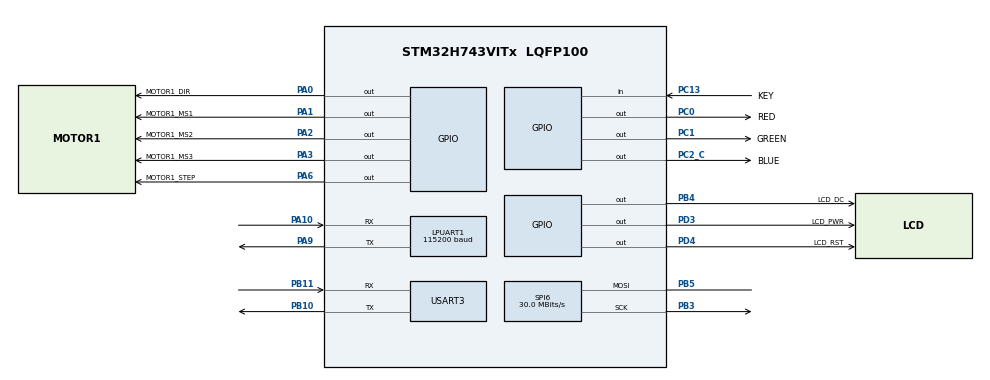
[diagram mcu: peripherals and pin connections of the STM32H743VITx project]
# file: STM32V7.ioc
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Bdma.LPUART1_RX.0.Direction=DMA_PERIPH_TO_MEMORY
Bdma.LPUART1_RX.0.EventEnable=DISABLE
Bdma.LPUART1_RX.0.Instance=BDMA_Channel0
Bdma.LPUART1_RX.0.MemDataAlignment=DMA_MDATAALIGN_BYTE
Bdma.LPUART1_RX.0.MemInc=DMA_MINC_ENABLE
Bdma.LPUART1_RX.0.Mode=DMA_NORMAL
Bdma.LPUART1_RX.0.PeriphDataAlignment=DMA_PDATAALIGN_BYTE
Bdma.LPUART1_RX.0.PeriphInc=DMA_PINC_DISABLE
Bdma.LPUART1_RX.0.Polarity=HAL_DMAMUX_REQ_GEN_RISING
Bdma.LPUART1_RX.0.Priority=DMA_PRIORITY_MEDIUM
Bdma.LPUART1_RX.0.RequestNumber=1
Bdma.LPUART1_RX.0.SignalID=NONE
Bdma.LPUART1_RX.0.SyncEnable=DISABLE
Bdma.LPUART1_RX.0.SyncPolarity=HAL_DMAMUX_SYNC_NO_EVENT
Bdma.LPUART1_RX.0.SyncRequestNumber=1
Bdma.LPUART1_RX.0.SyncSignalID=NONE
Bdma.LPUART1_TX.1.Direction=DMA_MEMORY_TO_PERIPH
Bdma.LPUART1_TX.1.EventEnable=DISABLE
Bdma.LPUART1_TX.1.Instance=BDMA_Channel1
Bdma.LPUART1_TX.1.MemDataAlignment=DMA_MDATAALIGN_BYTE
Bdma.LPUART1_TX.1.MemInc=DMA_MINC_ENABLE
Bdma.LPUART1_TX.1.Mode=DMA_NORMAL
Bdma.LPUART1_TX.1.PeriphDataAlignment=DMA_PDATAALIGN_BYTE
Bdma.LPUART1_TX.1.PeriphInc=DMA_PINC_DISABLE
Bdma.LPUART1_TX.1.Polarity=HAL_DMAMUX_REQ_GEN_RISING
Bdma.LPUART1_TX.1.Priority=DMA_PRIORITY_MEDIUM
Bdma.LPUART1_TX.1.RequestNumber=1
Bdma.LPUART1_TX.1.SignalID=NONE
Bdma.LPUART1_TX.1.SyncEnable=DISABLE
Bdma.LPUART1_TX.1.SyncPolarity=HAL_DMAMUX_SYNC_NO_EVENT
Bdma.LPUART1_TX.1.SyncRequestNumber=1
Bdma.LPUART1_TX.1.SyncSignalID=NONE
Bdma.Request0=LPUART1_RX
Bdma.Request1=LPUART1_TX
Bdma.RequestsNb=2
CORTEX_M7.AccessPermission-Cortex_Memory_Protection_Unit_Region1_Settings=MPU_REGION_PRIV_RO
CORTEX_M7.AccessPermission-Cortex_Memory_Protection_Unit_Region2_Settings=MPU_REGION_FULL_ACCESS
CORTEX_M7.BaseAddress-Cortex_Memory_Protection_Unit_Region0_Settings=0x90000000
CORTEX_M7.BaseAddress-Cortex_Memory_Protection_Unit_Region1_Settings=0x90000000
CORTEX_M7.BaseAddress-Cortex_Memory_Protection_Unit_Region2_Settings=0x38000000
CORTEX_M7.CPU_DCache=Enabled
CORTEX_M7.CPU_ICache=Enabled
CORTEX_M7.DisableExec-Cortex_Memory_Protection_Unit_Region0_Settings=MPU_INSTRUCTION_ACCESS_DISABLE
CORTEX_M7.Enable-Cortex_Memory_Protection_Unit_Region0_Settings=MPU_REGION_ENABLE
CORTEX_M7.Enable-Cortex_Memory_Protection_Unit_Region1_Settings=MPU_REGION_ENABLE
CORTEX_M7.Enable-Cortex_Memory_Protection_Unit_Region2_Settings=MPU_REGION_ENABLE
CORTEX_M7.IsBufferable-Cortex_Memory_Protection_Unit_Region0_Settings=MPU_ACCESS_NOT_BUFFERABLE
CORTEX_M7.IsBufferable-Cortex_Memory_Protection_Unit_Region1_Settings=MPU_ACCESS_BUFFERABLE
CORTEX_M7.IsBufferable-Cortex_Memory_Protection_Unit_Region2_Settings=MPU_ACCESS_BUFFERABLE
CORTEX_M7.IsCacheable-Cortex_Memory_Protection_Unit_Region0_Settings=MPU_ACCESS_NOT_CACHEABLE
CORTEX_M7.IsCacheable-Cortex_Memory_Protection_Unit_Region1_Settings=MPU_ACCESS_CACHEABLE
CORTEX_M7.IsCacheable-Cortex_Memory_Protection_Unit_Region2_Settings=MPU_ACCESS_NOT_CACHEABLE
CORTEX_M7.IsShareable-Cortex_Memory_Protection_Unit_Region2_Settings=MPU_ACCESS_SHAREABLE
CORTEX_M7.MPU_Control=MPU_PRIVILEGED_DEFAULT
CORTEX_M7.Size-Cortex_Memory_Protection_Unit_Region0_Settings=MPU_REGION_SIZE_256MB
CORTEX_M7.Size-Cortex_Memory_Protection_Unit_Region1_Settings=MPU_REGION_SIZE_8MB
CORTEX_M7.Size-Cortex_Memory_Protection_Unit_Region2_Settings=MPU_REGION_SIZE_16KB
CORTEX_M7.TypeExtField-Cortex_Memory_Protection_Unit_Region0_Settings=MPU_TEX_LEVEL1
CORTEX_M7.TypeExtField-Cortex_Memory_Protection_Unit_Region1_Settings=MPU_TEX_LEVEL1
CORTEX_M7.TypeExtField-Cortex_Memory_Protection_Unit_Region2_Settings=MPU_TEX_LEVEL1
Dma.Request0=USART3_RX
Dma.Request1=USART3_TX
Dma.USART3_RX.0.Direction=DMA_PERIPH_TO_MEMORY
Dma.USART3_RX.0.EventEnable=DISABLE
Dma.USART3_RX.0.FIFOMode=DMA_FIFOMODE_DISABLE
Dma.USART3_RX.0.Instance=DMA1_Stream0
Dma.USART3_RX.0.MemDataAlignment=DMA_MDATAALIGN_BYTE
Dma.USART3_RX.0.MemInc=DMA_MINC_ENABLE
Dma.USART3_RX.0.Mode=DMA_NORMAL
Dma.USART3_RX.0.PeriphDataAlignment=DMA_PDATAALIGN_BYTE
Dma.USART3_RX.0.PeriphInc=DMA_PINC_DISABLE
Dma.USART3_RX.0.Polarity=HAL_DMAMUX_REQ_GEN_RISING
Dma.USART3_RX.0.Priority=DMA_PRIORITY_MEDIUM
Dma.USART3_RX.0.RequestNumber=1
Dma.USART3_RX.0.SignalID=NONE
Dma.USART3_RX.0.SyncEnable=DISABLE
Dma.USART3_RX.0.SyncPolarity=HAL_DMAMUX_SYNC_NO_EVENT
Dma.USART3_RX.0.SyncRequestNumber=1
Dma.USART3_RX.0.SyncSignalID=NONE
Dma.USART3_TX.1.Direction=DMA_MEMORY_TO_PERIPH
Dma.USART3_TX.1.EventEnable=DISABLE
Dma.USART3_TX.1.FIFOMode=DMA_FIFOMODE_DISABLE
Dma.USART3_TX.1.Instance=DMA1_Stream1
Dma.USART3_TX.1.MemDataAlignment=DMA_MDATAALIGN_BYTE
Dma.USART3_TX.1.MemInc=DMA_MINC_ENABLE
Dma.USART3_TX.1.Mode=DMA_NORMAL
Dma.USART3_TX.1.PeriphDataAlignment=DMA_PDATAALIGN_BYTE
Dma.USART3_TX.1.PeriphInc=DMA_PINC_DISABLE
Dma.USART3_TX.1.Polarity=HAL_DMAMUX_REQ_GEN_RISING
Dma.USART3_TX.1.Priority=DMA_PRIORITY_MEDIUM
Dma.USART3_TX.1.RequestNumber=1
Dma.USART3_TX.1.SignalID=NONE
Dma.USART3_TX.1.SyncEnable=DISABLE
Dma.USART3_TX.1.SyncPolarity=HAL_DMAMUX_SYNC_NO_EVENT
Dma.USART3_TX.1.SyncRequestNumber=1
Dma.USART3_TX.1.SyncSignalID=NONE
LPUART1.BaudRate=115200
LPUART1.ClockPrescaler=UART_PRESCALER_DIV1
LPUART1.DMADisableonRxErrorParam=UART_ADVFEATURE_DMA_ENABLEONRXERROR
LPUART1.DataInvertParam=UART_ADVFEATURE_DATAINV_DISABLE
LPUART1.FIFOMode=UART_FIFOMODE_DISABLE
LPUART1.MSBFirstParam=UART_ADVFEATURE_MSBFIRST_DISABLE
LPUART1.OneBitSampling=UART_ONE_BIT_SAMPLE_DISABLE
LPUART1.OverrunDisableParam=UART_ADVFEATURE_OVERRUN_ENABLE
Mcu.Family=STM32H7
Mcu.Name=STM32H743VITx
Mcu.Package=LQFP100
NVIC.BDMA_Channel0_IRQn=true\:0\:0\:true\:false\:true\:false\:true
NVIC.BDMA_Channel1_IRQn=true\:0\:0\:true\:false\:true\:false\:true
NVIC.DMA1_Stream0_IRQn=true\:0\:0\:true\:false\:true\:false\:true
NVIC.DMA1_Stream1_IRQn=true\:0\:0\:true\:false\:true\:false\:true
NVIC.LPUART1_IRQn=true\:3\:0\:true\:false\:true\:true\:true
NVIC.PriorityGroup=NVIC_PRIORITYGROUP_4
NVIC.TIM3_IRQn=true\:2\:0\:true\:false\:true\:true\:true
NVIC.USART3_IRQn=true\:3\:0\:true\:false\:true\:true\:true
PA0.GPIO_Label=MOTOR1_DIR
PA0.GPIO_PuPd=GPIO_PULLDOWN
PA0.GPIO_Speed=GPIO_SPEED_FREQ_VERY_HIGH
PA0.Signal=GPIO_Output
PA1.GPIO_Label=MOTOR1_MS1
PA1.GPIO_PuPd=GPIO_PULLDOWN
PA1.Signal=GPIO_Output
PA10.GPIO_Mode=GPIO_MODE_AF_PP
PA10.GPIO_PuPd=GPIO_PULLUP
PA10.GPIO_Speed=GPIO_SPEED_FREQ_HIGH
PA10.Mode=Asynchronous
PA10.Signal=LPUART1_RX
PA13\ (JTMS/SWDIO).Mode=Serial_Wire
PA13\ (JTMS/SWDIO).Signal=DEBUG_JTMS-SWDIO
PA14\ (JTCK/SWCLK).Mode=Serial_Wire
PA14\ (JTCK/SWCLK).Signal=DEBUG_JTCK-SWCLK
PA2.GPIO_Label=MOTOR1_MS2
PA2.GPIO_PuPd=GPIO_PULLDOWN
PA2.Signal=GPIO_Output
PA3.GPIO_Label=MOTOR1_MS3
PA3.GPIO_PuPd=GPIO_PULLDOWN
PA3.Signal=GPIO_Output
PA6.GPIO_Label=MOTOR1_STEP
PA6.GPIO_PuPd=GPIO_PULLDOWN
PA6.GPIO_Speed=GPIO_SPEED_FREQ_VERY_HIGH
PA6.Signal=GPIO_Output
PA9.GPIO_Mode=GPIO_MODE_AF_PP
PA9.GPIO_PuPd=GPIO_PULLUP
PA9.GPIO_Speed=GPIO_SPEED_FREQ_HIGH
PA9.Mode=Asynchronous
PA9.PinAttribute=Free
PA9.Signal=LPUART1_TX
PB10.GPIO_PuPd=GPIO_PULLUP
PB10.GPIO_Speed=GPIO_SPEED_FREQ_HIGH
PB10.Mode=Asynchronous
PB10.Signal=USART3_TX
PB11.GPIO_PuPd=GPIO_PULLUP
PB11.GPIO_Speed=GPIO_SPEED_FREQ_HIGH
PB11.Mode=Asynchronous
PB11.Signal=USART3_RX
PB3\ (JTDO/TRACESWO).GPIO_PuPd=GPIO_NOPULL
PB3\ (JTDO/TRACESWO).GPIO_Speed=GPIO_SPEED_FREQ_LOW
PB3\ (JTDO/TRACESWO).Mode=Simplex_Bidirectional_Master
PB3\ (JTDO/TRACESWO).Signal=SPI6_SCK
PB4\ (NJTRST).GPIO_Label=LCD_DC
PB4\ (NJTRST).GPIO_PuPd=GPIO_PULLUP
PB4\ (NJTRST).GPIO_Speed=GPIO_SPEED_FREQ_LOW
PB4\ (NJTRST).PinState=GPIO_PIN_RESET
PB4\ (NJTRST).Signal=GPIO_Output
PB5.GPIO_PuPd=GPIO_NOPULL
PB5.GPIO_Speed=GPIO_SPEED_FREQ_LOW
PB5.Mode=Simplex_Bidirectional_Master
PB5.Signal=SPI6_MOSI
PC0.GPIO_Label=RED
PC0.GPIO_PuPd=GPIO_PULLUP
PC0.GPIO_Speed=GPIO_SPEED_FREQ_LOW
PC0.PinState=GPIO_PIN_SET
PC0.Signal=GPIO_Output
PC1.GPIO_Label=GREEN
PC1.GPIO_PuPd=GPIO_PULLUP
PC1.GPIO_Speed=GPIO_SPEED_FREQ_LOW
PC1.PinAttribute=Free
PC1.PinState=GPIO_PIN_SET
PC1.Signal=GPIO_Output
PC13.GPIO_Label=KEY
PC13.GPIO_PuPd=GPIO_PULLUP
PC13.Signal=GPIO_Input
PC14-OSC32_IN\ (OSC32_IN).Mode=LSE-External-Oscillator
PC14-OSC32_IN\ (OSC32_IN).Signal=RCC_OSC32_IN
PC15-OSC32_OUT\ (OSC32_OUT).Mode=LSE-External-Oscillator
PC15-OSC32_OUT\ (OSC32_OUT).Signal=RCC_OSC32_OUT
PC2_C.GPIO_Label=BLUE
PC2_C.GPIO_PuPd=GPIO_PULLUP
PC2_C.GPIO_Speed=GPIO_SPEED_FREQ_LOW
PC2_C.PinAttribute=Free
PC2_C.PinState=GPIO_PIN_SET
PC2_C.Signal=GPIO_Output
PD3.GPIO_Label=LCD_PWR
PD3.GPIO_PuPd=GPIO_PULLUP
PD3.GPIO_Speed=GPIO_SPEED_FREQ_LOW
PD3.PinState=GPIO_PIN_RESET
PD3.Signal=GPIO_Output
PD4.GPIO_Label=LCD_RST
PD4.GPIO_PuPd=GPIO_PULLUP
PD4.GPIO_Speed=GPIO_SPEED_FREQ_LOW
PD4.PinState=GPIO_PIN_RESET
PD4.Signal=GPIO_Output
PH0-OSC_IN\ (PH0).Mode=HSE-External-Oscillator
PH0-OSC_IN\ (PH0).Signal=RCC_OSC_IN
PH1-OSC_OUT\ (PH1).Mode=HSE-External-Oscillator
PH1-OSC_OUT\ (PH1).Signal=RCC_OSC_OUT
ProjectManager.HeapSize=0x800
ProjectManager.StackSize=0x800
ProjectManager.TargetToolchain=MDK-ARM V5.32
RCC.ADCFreq_Value=480000000
RCC.APB1Freq_Value=120000000
RCC.APB2Freq_Value=120000000
RCC.APB3Freq_Value=120000000
RCC.APB4Freq_Value=120000000
RCC.CortexFreq_Value=480000000
RCC.D1PPRE=RCC_APB3_DIV2
RCC.D2PPRE1=RCC_APB1_DIV2
RCC.D2PPRE2=RCC_APB2_DIV2
RCC.D3PPRE=RCC_APB4_DIV2
RCC.DIVM1=1
RCC.DIVM2=1
RCC.DIVM3=1
RCC.DIVN1=80
RCC.DIVN2=80
RCC.DIVN3=80
RCC.HCLKFreq_Value=240000000
RCC.HPRE=RCC_HCLK_DIV2
RCC.HSE_VALUE=12000000
RCC.PLL2FRACN=0
RCC.PLL3FRACN=0
RCC.PLL3_VCI_Range-AdvancedSettings=RCC_PLL3VCIRANGE_3
RCC.PLLFRACN=0
RCC.PLLSourceVirtual=RCC_PLLSOURCE_HSE
RCC.PWR_Regulator_Voltage_Scale=PWR_REGULATOR_VOLTAGE_SCALE0
RCC.ProductRev=revV
RCC.SYSCLKFreq_VALUE=480000000
RCC.SYSCLKSource=RCC_SYSCLKSOURCE_PLLCLK
RCC.SupplySource=PWR_LDO_SUPPLY
RCC.USBFreq_Value=480000000
SPI6.BaudRatePrescaler=SPI_BAUDRATEPRESCALER_4
SPI6.CLKPhase=SPI_PHASE_2EDGE
SPI6.CLKPolarity=SPI_POLARITY_HIGH
SPI6.CalculateBaudRate=30.0 MBits/s
SPI6.DataSize=SPI_DATASIZE_8BIT
SPI6.Direction=SPI_DIRECTION_1LINE
SPI6.Mode=SPI_MODE_MASTER
SPI6.VirtualType=VM_MASTER
TIM3.Period=49
TIM3.Prescaler=47
USART3.VirtualMode-Asynchronous=VM_ASYNC
VP_TIM3_VS_ClockSourceINT.Mode=Internal
board=custom

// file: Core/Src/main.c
/* USER CODE BEGIN Header */
/**
 ******************************************************************************
 * @file           : main.c
 * @brief          : Main program body
 ******************************************************************************
 * @attention
 *
 * <h2><center>&copy; Copyright (c) 2021 STMicroelectronics.
 * All rights reserved.</center></h2>
 *
 * This software component is licensed by ST under BSD 3-Clause license,
 * the "License"; You may not use this file except in compliance with the
 * License. You may obtain a copy of the License at:
 *                        opensource.org/licenses/BSD-3-Clause
 *
 ******************************************************************************
 */
/* USER CODE END Header */
#include "main.h"
#include "bdma.h"
#include "dma.h"
#include "usart.h"
#include "spi.h"
#include "tim.h"
#include "gpio.h"

/* USER CODE BEGIN PV */
static OS_TCB AppTaskTCB;
static CPU_STK AppTaskSTK[512];
/* USER CODE END PV */

void SystemClock_Config(void);
static void MPU_Config(void);
/* USER CODE BEGIN PFP */
void app_task(void *p_arg);
/* USER CODE END PFP */

int main(void)
{
  /* USER CODE BEGIN 1 */
  OS_ERR err;
  /* USER CODE END 1 */

  /* MPU Configuration--------------------------------------------------------*/
  MPU_Config();

  /* Enable I-Cache---------------------------------------------------------*/
  SCB_EnableICache();

  /* Enable D-Cache---------------------------------------------------------*/
  SCB_EnableDCache();

  /* MCU Configuration--------------------------------------------------------*/

  /* Reset of all peripherals, Initializes the Flash interface and the Systick. */
  HAL_Init();

  /* Configure the system clock */
  SystemClock_Config();

  /* Initialize all configured peripherals */
  MX_GPIO_Init();
  MX_BDMA_Init();
  MX_DMA_Init();
  MX_LPUART1_UART_Init();
  MX_USART3_UART_Init();
  MX_SPI6_Init();
  MX_TIM3_Init();
  /* USER CODE BEGIN 2 */
  OSInit(&err);
  OSTaskCreate(&AppTaskTCB, "App Task", app_task, 0, 2, AppTaskSTK, 512 / 10,
               512, 0, 0, 0, OS_OPT_TASK_STK_CHK | OS_OPT_TASK_STK_CLR, &err);
  OSStart(&err);
  /* USER CODE END 2 */

  /* Infinite loop */

}

void SystemClock_Config(void)
{
  LL_FLASH_SetLatency(LL_FLASH_LATENCY_4);
  while(LL_FLASH_GetLatency()!= LL_FLASH_LATENCY_4)
  {
  }
  LL_PWR_ConfigSupply(LL_PWR_LDO_SUPPLY);
  LL_PWR_SetRegulVoltageScaling(LL_PWR_REGU_VOLTAGE_SCALE0);
  LL_RCC_HSE_Enable();

   /* Wait till HSE is ready */
  while(LL_RCC_HSE_IsReady() != 1)
  {

  }
  LL_RCC_PLL_SetSource(LL_RCC_PLLSOURCE_HSE);
  LL_RCC_PLL1P_Enable();
  LL_RCC_PLL1R_Enable();
  LL_RCC_PLL1_SetVCOInputRange(LL_RCC_PLLINPUTRANGE_8_16);
  LL_RCC_PLL1_SetVCOOutputRange(LL_RCC_PLLVCORANGE_WIDE);
  LL_RCC_PLL1_SetM(1);
  LL_RCC_PLL1_SetN(80);
  LL_RCC_PLL1_SetP(2);
  LL_RCC_PLL1_SetQ(2);
  LL_RCC_PLL1_SetR(2);
  LL_RCC_PLL1_Enable();

   /* Wait till PLL is ready */
  while(LL_RCC_PLL1_IsReady() != 1)
  {
  }

   /* Intermediate AHB prescaler 2 when target frequency clock is higher than 80 MHz */
   LL_RCC_SetAHBPrescaler(LL_RCC_AHB_DIV_2);

  LL_RCC_SetSysClkSource(LL_RCC_SYS_CLKSOURCE_PLL1);
  LL_RCC_SetSysPrescaler(LL_RCC_SYSCLK_DIV_1);
  LL_RCC_SetAHBPrescaler(LL_RCC_AHB_DIV_2);
  LL_RCC_SetAPB1Prescaler(LL_RCC_APB1_DIV_2);
  LL_RCC_SetAPB2Prescaler(LL_RCC_APB2_DIV_2);
  LL_RCC_SetAPB3Prescaler(LL_RCC_APB3_DIV_2);
  LL_RCC_SetAPB4Prescaler(LL_RCC_APB4_DIV_2);
  LL_SetSystemCoreClock(480000000);

   /* Update the time base */
  if (HAL_InitTick (TICK_INT_PRIORITY) != HAL_OK)
  {
    Error_Handler();
  }
}

/* MPU Configuration */

void MPU_Config(void)
{

  /* Disables the MPU */
  LL_MPU_Disable();
  /** Initializes and configures the Region and the memory to be protected
  */
  LL_MPU_ConfigRegion(LL_MPU_REGION_NUMBER0, 0x0, 0x90000000, LL_MPU_REGION_NO_ACCESS|LL_MPU_INSTRUCTION_ACCESS_DISABLE|LL_MPU_ACCESS_NOT_SHAREABLE|LL_MPU_ACCESS_NOT_CACHEABLE|LL_MPU_ACCESS_NOT_BUFFERABLE);
  LL_MPU_EnableRegion(LL_MPU_REGION_NUMBER0);
  /** Initializes and configures the Region and the memory to be protected
  */
  LL_MPU_ConfigRegion(LL_MPU_REGION_NUMBER1, 0x0, 0x90000000, LL_MPU_REGION_SIZE_8MB|LL_MPU_REGION_PRIV_RO|LL_MPU_INSTRUCTION_ACCESS_ENABLE|LL_MPU_ACCESS_NOT_SHAREABLE|LL_MPU_ACCESS_CACHEABLE|LL_MPU_ACCESS_BUFFERABLE);
  LL_MPU_EnableRegion(LL_MPU_REGION_NUMBER1);
  /** Initializes and configures the Region and the memory to be protected
  */
  LL_MPU_ConfigRegion(LL_MPU_REGION_NUMBER2, 0x0, 0x38000000, LL_MPU_REGION_SIZE_16KB|LL_MPU_REGION_FULL_ACCESS|LL_MPU_INSTRUCTION_ACCESS_ENABLE|LL_MPU_ACCESS_SHAREABLE|LL_MPU_ACCESS_NOT_CACHEABLE|LL_MPU_ACCESS_BUFFERABLE);
  LL_MPU_EnableRegion(LL_MPU_REGION_NUMBER2);
  /* Enables the MPU */
  LL_MPU_Enable(LL_MPU_CTRL_PRIVILEGED_DEFAULT);

}

void Error_Handler(void)
{
  __disable_irq();
  while (1) {
  }
}

#ifdef  USE_FULL_ASSERT
/**
  * @brief  Reports the name of the source file and the source line number
  *         where the assert_param error has occurred.
  * @param  file: pointer to the source file name
  * @param  line: assert_param error line source number
  * @retval None
  */
void assert_failed(uint8_t *file, uint32_t line)
{
  /* USER CODE BEGIN 6 */
  /* User can add his own implementation to report the file name and line
     number,
     ex: printf("Wrong parameters value: file %s on line %d\r\n", file, line) */
  /* USER CODE END 6 */
}
#endif /* USE_FULL_ASSERT */

/************************ (C) COPYRIGHT STMicroelectronics *****END OF FILE****/
